# max32657 register map
Vendor: Maxim-Integrated; Series: ARMCM33; File version: 1.1
MAX32657 32-bit ARM Cortex-M33 microcontroller with TrustZone, 1MB of flash, 256KB of SRAM, 64KB of Boot ROM.
CPU: CM4 r2p1, little endian, MPU, FPU, 3 interrupt priority bits
Registers are 32-bit, read-write, reset 0x0 unless marked. A register's access mark holds for its fields unless they carry their own. Offsets are from the block's base; lines under a group give offsets from that group; [hi:lo] are bit positions; {n}, {i} and the like mark numbered series; 'fields as' and 'values as' point back to an identical list; <NAME> marks a mode.

## Memory map
0x40090000 NSPC size 0x1000 — Non-Secure Privilege Controller.
0x50000000 GCR size 0x400 — Global Control Registers.
0x50000400 SIR size 0x400 — System Initialization Registers.
0x50000800 FCR size 0x400 — Function Control Register.
0x50003000 WDT size 0x400 — Windowed Watchdog Timer
0x50004800 RSTZ size 0x400 — RSTZ Controller
0x50004C00 BOOST size 0x400 — Boost Controller
0x50005400 TRIMSIR size 0x400 — Trim System Initilazation Registers.
0x50006000 RTC size 0x400 — Real Time Clock and Alarm.
0x50006400 WUT size 0x400 — 32-bit reloadable timer that can be used for timing and wakeup.
0x50006800 PWRSEQ size 0x400 — Power Sequencer / Low Power Control Register.
0x50006C00 MCR size 0x400 — Misc Control.
0x50007400 AES size 0x400 — AES Keys.
0x50007800 AESKEYS size 0x400 — AES Key Registers.
0x50008000 GPIO0 size 0x1000 — Individual I/O for each GPIO
0x5000F000 CRC size 0x1000 — CRC Registers.
0x50010000 TMR size 0x1000 — Low-Power Configurable Timer
0x50011000 TMR1 size 0x1000 — Low-Power Configurable Timer 1
0x50012000 TMR2 size 0x1000 — Low-Power Configurable Timer 2
0x50013000 TMR3 size 0x1000 — Low-Power Configurable Timer 3
0x50014000 TMR4 size 0x1000 — Low-Power Configurable Timer 4
0x50015000 TMR5 size 0x1000 — Low-Power Configurable Timer 5
0x50018000 I3C0 size 0x1000 — Improved Inter-Integrated Circuit.
0x50028000 DMA size 0x1000 — DMA Controller Fully programmable, chaining capable DMA channels.
0x50029000 FLC size 0x400 — Flash Memory Control.
0x5002A000 ICC size 0x1000 — Instruction Cache Controller Registers
0x50035000 DMA1 size 0x1000 — DMA Controller Fully programmable, chaining capable DMA channels. 1
0x50042000 UART size 0x1000 — UART Low Power Registers
0x50046000 SPI size 0x1000 — SPI peripheral.
0x5004D000 TRNG size 0x1000 — Random Number Generator.
0x50090000 SPC size 0x1000 — Secure Privilege Controller.
0x50091000 MPC size 0x1000 — Memory Protection Controller.
0x50092000 MPC1 size 0x1000 — Memory Protection Controller. 1
0x50093000 MPC2 size 0x1000 — Memory Protection Controller. 2
0x50094000 MPC3 size 0x1000 — Memory Protection Controller. 3
0x50095000 MPC4 size 0x1000 — Memory Protection Controller. 4
0x50096000 MPC5 size 0x1000 — Memory Protection Controller. 5

## Interrupts
1 WWDT (WDT)
3 RTC — RTC interrupt.
4 TRNG — TRNG interrupt.
5 TMR
6 TMR1 — TMR1 IRQ
7 TMR2 — TMR2 IRQ
8 TMR3 — TMR3 IRQ
9 TMR4 — TMR4 IRQ
10 TMR5 — TMR5 IRQ
23 FLC — FLC Interrupt.
24 GPIO0 — GPIO0 interrupt.
26 I3C0 — I3C0 IRQ
32 DMA0_CH0 (DMA)
33 DMA0_CH1 (DMA)
34 DMA0_CH2 (DMA)
35 DMA0_CH3 (DMA)
36 DMA1_CH0 (DMA1)
37 DMA1_CH1 (DMA1)
38 DMA1_CH2 (DMA1)
39 DMA1_CH3 (DMA1)
46 BOOST
53 WUT — WUT IRQ
56 SPI0 (SPI)

## AESKEYS — AES Key Registers.
Base 0x50007800
{0x0+4i} KEY{i} (i=0..7) — AES Key {i}.

## AES — AES Keys.
Base 0x50007400
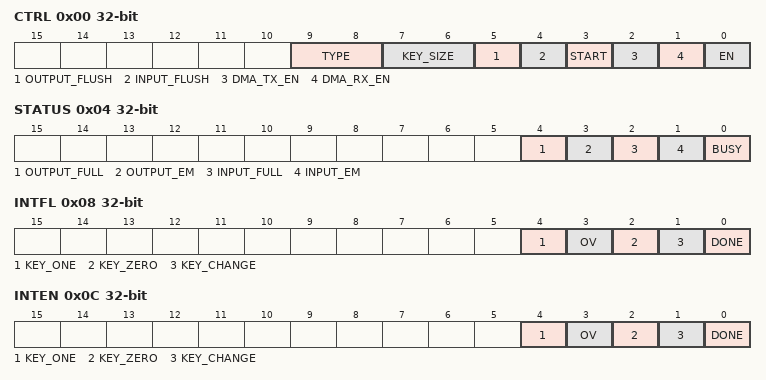
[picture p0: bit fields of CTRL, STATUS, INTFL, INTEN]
0x00 CTRL — AES Control Register
  [9:8] TYPE — Encryption Type Selection
  [7:6] KEY_SIZE — Encryption Key Size
    0=AES128 (128 Bits.); 1=AES192 (192 Bits.); 2=AES256 (256 Bits.)
  [5] OUTPUT_FLUSH — Flush the data output FIFO
  [4] INPUT_FLUSH — Flush the data input FIFO
  [3] START — Start AES Calculation
  [2] DMA_TX_EN — DMA Request To Write Data Input FIFO
  [1] DMA_RX_EN — DMA Request To Read Data Output FIFO
  [0] EN — AES Enable
0x04 STATUS — AES Status Register
  [4] OUTPUT_FULL — Data output FIFO full status
  [3] OUTPUT_EM — Data output FIFO empty status
  [2] INPUT_FULL — Data input FIFO full status
  [1] INPUT_EM — Data input FIFO empty status
  [0] BUSY — AES Busy Status
0x08 INTFL — AES Interrupt Flag Register
  [4] KEY_ONE
  [3] OV — Data Output FIFO Overrun Interrupt
  [2] KEY_ZERO — External AES Key Zero Interrupt
  [1] KEY_CHANGE — External AES Key Changed Interrupt
  [0] DONE — AES Done Interrupt
0x0C INTEN — AES Interrupt Enable Register
  [4] KEY_ONE
  [3] OV — Data Output FIFO Overrun Interrupt Enable
  [2] KEY_ZERO — External AES Key Zero Interrupt Enable
  [1] KEY_CHANGE — External AES Key Changed Interrupt Enable
  [0] DONE — AES Done Interrupt Enable
0x10 FIFO — AES Data Register
  [0] DATA — AES FIFO
